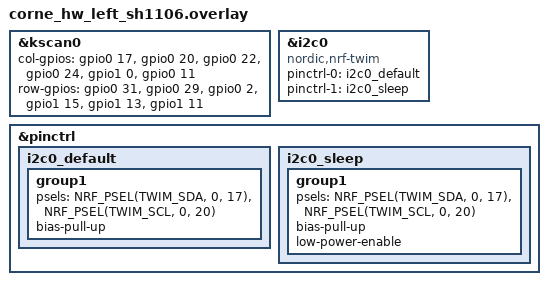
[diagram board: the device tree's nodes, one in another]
/*
 * Copyright (c) 2020 The ZMK Contributors
 *
 * SPDX-License-Identifier: MIT
 */

#include <dt-bindings/pinctrl/nrf-pinctrl.h>
#include <dt-bindings/i2c/i2c.h>
#include "corne_hw.dtsi"

&kscan0 {
    col-gpios = <&gpio0 17  (GPIO_ACTIVE_HIGH | GPIO_PULL_DOWN)>,  /* D6 = P1.00 */
                <&gpio0 20  (GPIO_ACTIVE_HIGH | GPIO_PULL_DOWN)>,  /* D6 = P1.00 */
                <&gpio0 22  (GPIO_ACTIVE_HIGH | GPIO_PULL_DOWN)>,  /* D6 = P1.00 */
                <&gpio0 24  (GPIO_ACTIVE_HIGH | GPIO_PULL_DOWN)>,  /* D6 = P1.00 */
                <&gpio1 0  (GPIO_ACTIVE_HIGH | GPIO_PULL_DOWN)>,  /* D6 = P1.00 */
                <&gpio0 11 (GPIO_ACTIVE_HIGH | GPIO_PULL_DOWN)>;  /* D7 = P0.11 */

    row-gpios = 
                <&gpio0 31  GPIO_ACTIVE_HIGH>,  /* Col 0 = P0.02 */
                <&gpio0 29  GPIO_ACTIVE_HIGH>,  /* Col 0 = P0.02 */
                <&gpio0 2  GPIO_ACTIVE_HIGH>,  /* Col 0 = P0.02 */
                <&gpio1 15 GPIO_ACTIVE_HIGH>,  /* Col 1 = P1.15 */
                <&gpio1 13 GPIO_ACTIVE_HIGH>,  /* Col 2 = P1.13 */
                <&gpio1 11 GPIO_ACTIVE_HIGH>;  /* Col 3 = P1.11 */
};

// OLED configuration - testing SH1106 driver
// Pins: SDA=P0.17, SCL=P0.20 (board defaults)
&i2c0 {
    compatible = "nordic,nrf-twim";  // Force TWIM (DMA) driver
    status = "okay";
    pinctrl-0 = <&i2c0_default>;
    pinctrl-1 = <&i2c0_sleep>;
    pinctrl-names = "default", "sleep";


};

// Add pinctrl configuration for I2C
&pinctrl {
    i2c0_default: i2c0_default {
        group1 {
            psels = <NRF_PSEL(TWIM_SDA, 0, 17)>,
                    <NRF_PSEL(TWIM_SCL, 0, 20)>;
            bias-pull-up;
        };
    };

    i2c0_sleep: i2c0_sleep {
        group1 {
            psels = <NRF_PSEL(TWIM_SDA, 0, 17)>,
                    <NRF_PSEL(TWIM_SCL, 0, 20)>;
            bias-pull-up;
            low-power-enable;
        };
    };
};
